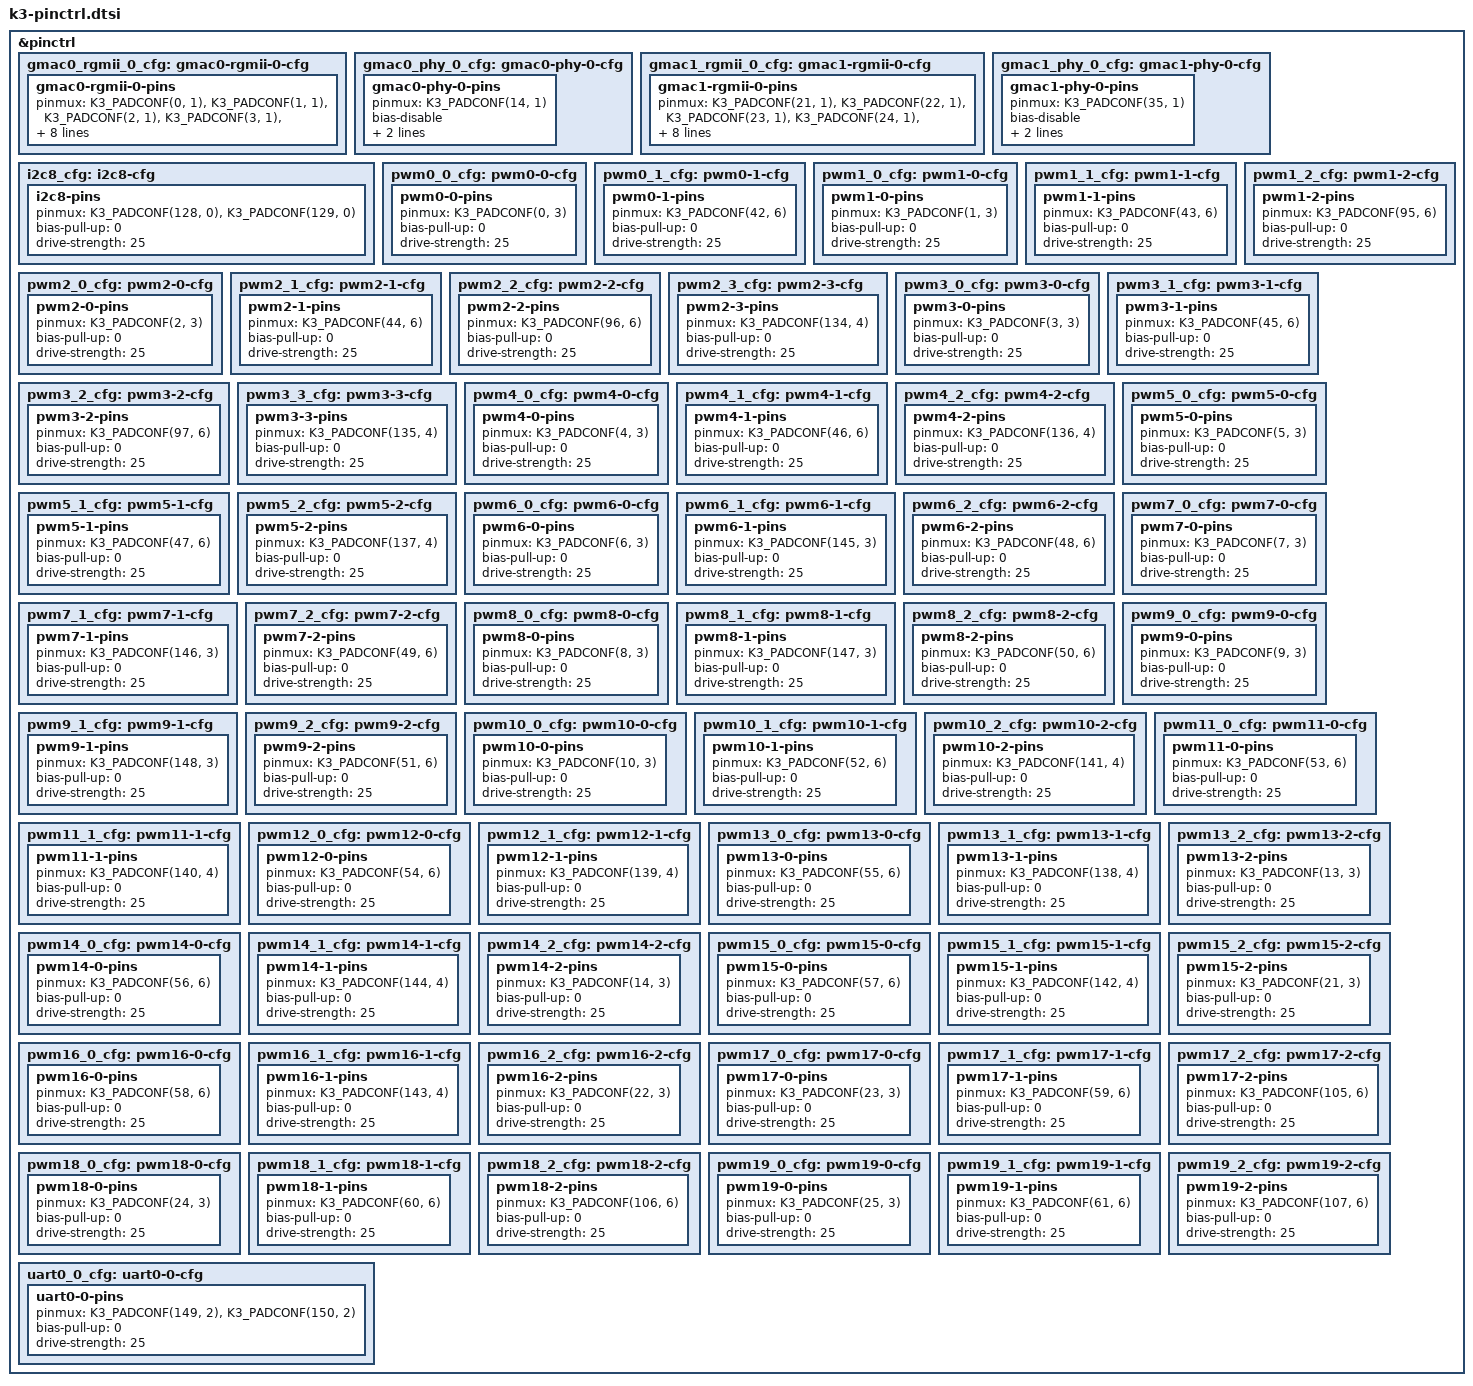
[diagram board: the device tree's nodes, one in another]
// SPDX-License-Identifier: GPL-2.0 OR MIT
/*
 * Copyright (c) 2026 Yixun Lan <dlan@kernel.org>
 */

#include <dt-bindings/gpio/gpio.h>

#define K3_PADCONF(pin, func) (((pin) << 16) | (func))

/* Map GPIO pin to each bank's <index, offset> */
#define K3_GPIO(x)	(x / 32) (x % 32)

&pinctrl {
	gmac0_rgmii_0_cfg: gmac0-rgmii-0-cfg {
		gmac0-rgmii-0-pins {
			pinmux = <K3_PADCONF(0, 1)>,	/* gmac0_rxdv */
				 <K3_PADCONF(1, 1)>,	/* gmac0_rx_d0 */
				 <K3_PADCONF(2, 1)>,	/* gmac0_rx_d1 */
				 <K3_PADCONF(3, 1)>,	/* gmac0_rx_clk */
				 <K3_PADCONF(4, 1)>,	/* gmac0_rx_d2 */
				 <K3_PADCONF(5, 1)>,	/* gmac0_rx_d3 */
				 <K3_PADCONF(6, 1)>,	/* gmac0_tx_d0 */
				 <K3_PADCONF(7, 1)>,	/* gmac0_tx_d1 */
				 <K3_PADCONF(8, 1)>,	/* gmac0_tx_clk */
				 <K3_PADCONF(9, 1)>,	/* gmac0_tx_d2 */
				 <K3_PADCONF(10, 1)>,	/* gmac0_tx_d3 */
				 <K3_PADCONF(11, 1)>,	/* gmac0_tx_en */
				 <K3_PADCONF(12, 1)>,	/* gmac0_mdc */
				 <K3_PADCONF(13, 1)>;	/* gmac0_mdio */

			bias-disable;
			drive-strength = <25>;
			power-source = <1800>;
		};

	};

	gmac0_phy_0_cfg: gmac0-phy-0-cfg {
		gmac0-phy-0-pins {
			pinmux = <K3_PADCONF(14, 1)>;   /* gmac0_int */

			bias-disable;
			drive-strength = <25>;
			power-source = <1800>;
		};
	};

	gmac1_rgmii_0_cfg: gmac1-rgmii-0-cfg {
		gmac1-rgmii-0-pins {
			pinmux = <K3_PADCONF(21, 1)>,	/* gmac1_rxdv  */
				 <K3_PADCONF(22, 1)>,	/* gmac1 rx d0 */
				 <K3_PADCONF(23, 1)>,	/* gmac1 rx d1 */
				 <K3_PADCONF(24, 1)>,	/* gmac1 rx_clk */
				 <K3_PADCONF(25, 1)>,	/* gmac1 rx d2 */
				 <K3_PADCONF(26, 1)>,	/* gmac1 rx d3 */
				 <K3_PADCONF(27, 1)>,	/* gmac1 tx d0 */
				 <K3_PADCONF(28, 1)>,	/* gmac1 tx d1 */
				 <K3_PADCONF(29, 1)>,	/* gmac1 tx clk */
				 <K3_PADCONF(30, 1)>,	/* gmac1 tx d2 */
				 <K3_PADCONF(31, 1)>,	/* gmac1 tx d3 */
				 <K3_PADCONF(32, 1)>,	/* gmac1 tx_en */
				 <K3_PADCONF(33, 1)>,	/* gmac1 mdc */
				 <K3_PADCONF(34, 1)>;	/* gmac1 mdio */

			bias-disable;
			drive-strength = <25>;
			power-source = <1800>;
		};
	};

	gmac1_phy_0_cfg: gmac1-phy-0-cfg {
		gmac1-phy-0-pins {
			pinmux = <K3_PADCONF(35, 1)>;	/* gmac1 int */

			bias-disable;
			drive-strength = <25>;
			power-source = <1800>;
		};
	};

	/omit-if-no-ref/
	i2c8_cfg: i2c8-cfg {
		i2c8-pins {
			pinmux = <K3_PADCONF(128, 0)>,	/* i2c8 scl */
				 <K3_PADCONF(129, 0)>;	/* i2c8 sda */

			bias-pull-up = <0>;
			drive-strength = <25>;
		};
	};

	/omit-if-no-ref/
	pwm0_0_cfg: pwm0-0-cfg {
		pwm0-0-pins {
			pinmux = <K3_PADCONF(0, 3)>;	/* pwm0 */

			bias-pull-up = <0>;
			drive-strength = <25>;
		};
	};

	/omit-if-no-ref/
	pwm0_1_cfg: pwm0-1-cfg {
		pwm0-1-pins {
			pinmux = <K3_PADCONF(42, 6)>;	/* pwm0 */

			bias-pull-up = <0>;
			drive-strength = <25>;
		};
	};

	/omit-if-no-ref/
	pwm1_0_cfg: pwm1-0-cfg {
		pwm1-0-pins {
			pinmux = <K3_PADCONF(1, 3)>;	/* pwm1 */

			bias-pull-up = <0>;
			drive-strength = <25>;
		};
	};

	/omit-if-no-ref/
	pwm1_1_cfg: pwm1-1-cfg {
		pwm1-1-pins {
			pinmux = <K3_PADCONF(43, 6)>;	/* pwm1 */

			bias-pull-up = <0>;
			drive-strength = <25>;
		};
	};

	/omit-if-no-ref/
	pwm1_2_cfg: pwm1-2-cfg {
		pwm1-2-pins {
			pinmux = <K3_PADCONF(95, 6)>;	/* pwm1 */

			bias-pull-up = <0>;
			drive-strength = <25>;
		};
	};

	/omit-if-no-ref/
	pwm2_0_cfg: pwm2-0-cfg {
		pwm2-0-pins {
			pinmux = <K3_PADCONF(2, 3)>;	/* pwm2 */

			bias-pull-up = <0>;
			drive-strength = <25>;
		};
	};

	/omit-if-no-ref/
	pwm2_1_cfg: pwm2-1-cfg {
		pwm2-1-pins {
			pinmux = <K3_PADCONF(44, 6)>;	/* pwm2 */

			bias-pull-up = <0>;
			drive-strength = <25>;
		};
	};

	/omit-if-no-ref/
	pwm2_2_cfg: pwm2-2-cfg {
		pwm2-2-pins {
			pinmux = <K3_PADCONF(96, 6)>;	/* pwm2 */

			bias-pull-up = <0>;
			drive-strength = <25>;
		};
	};

	/omit-if-no-ref/
	pwm2_3_cfg: pwm2-3-cfg {
		pwm2-3-pins {
			pinmux = <K3_PADCONF(134, 4)>;	/* pwm2 */

			bias-pull-up = <0>;
			drive-strength = <25>;
		};
	};

	/omit-if-no-ref/
	pwm3_0_cfg: pwm3-0-cfg {
		pwm3-0-pins {
			pinmux = <K3_PADCONF(3, 3)>;	/* pwm3 */

			bias-pull-up = <0>;
			drive-strength = <25>;
		};
	};

	/omit-if-no-ref/
	pwm3_1_cfg: pwm3-1-cfg {
		pwm3-1-pins {
			pinmux = <K3_PADCONF(45, 6)>;	/* pwm3 */

			bias-pull-up = <0>;
			drive-strength = <25>;
		};
	};

	/omit-if-no-ref/
	pwm3_2_cfg: pwm3-2-cfg {
		pwm3-2-pins {
			pinmux = <K3_PADCONF(97, 6)>;	/* pwm3 */

			bias-pull-up = <0>;
			drive-strength = <25>;
		};
	};

	/omit-if-no-ref/
	pwm3_3_cfg: pwm3-3-cfg {
		pwm3-3-pins {
			pinmux = <K3_PADCONF(135, 4)>;	/* pwm3 */

			bias-pull-up = <0>;
			drive-strength = <25>;
		};
	};

	/omit-if-no-ref/
	pwm4_0_cfg: pwm4-0-cfg {
		pwm4-0-pins {
			pinmux = <K3_PADCONF(4, 3)>;	/* pwm4 */

			bias-pull-up = <0>;
			drive-strength = <25>;
		};
	};

	/omit-if-no-ref/
	pwm4_1_cfg: pwm4-1-cfg {
		pwm4-1-pins {
			pinmux = <K3_PADCONF(46, 6)>;	/* pwm4 */

			bias-pull-up = <0>;
			drive-strength = <25>;
		};
	};

	/omit-if-no-ref/
	pwm4_2_cfg: pwm4-2-cfg {
		pwm4-2-pins {
			pinmux = <K3_PADCONF(136, 4)>;	/* pwm4 */

			bias-pull-up = <0>;
			drive-strength = <25>;
		};
	};

	/omit-if-no-ref/
	pwm5_0_cfg: pwm5-0-cfg {
		pwm5-0-pins {
			pinmux = <K3_PADCONF(5, 3)>;	/* pwm5 */

			bias-pull-up = <0>;
			drive-strength = <25>;
		};
	};

	/omit-if-no-ref/
	pwm5_1_cfg: pwm5-1-cfg {
		pwm5-1-pins {
			pinmux = <K3_PADCONF(47, 6)>;	/* pwm5 */

			bias-pull-up = <0>;
			drive-strength = <25>;
		};
	};

	/omit-if-no-ref/
	pwm5_2_cfg: pwm5-2-cfg {
		pwm5-2-pins {
			pinmux = <K3_PADCONF(137, 4)>;	/* pwm5 */

			bias-pull-up = <0>;
			drive-strength = <25>;
		};
	};

	/omit-if-no-ref/
	pwm6_0_cfg: pwm6-0-cfg {
		pwm6-0-pins {
			pinmux = <K3_PADCONF(6, 3)>;	/* pwm6 */

			bias-pull-up = <0>;
			drive-strength = <25>;
		};
	};

	/omit-if-no-ref/
	pwm6_1_cfg: pwm6-1-cfg {
		pwm6-1-pins {
			pinmux = <K3_PADCONF(145, 3)>;	/* pwm6 */

			bias-pull-up = <0>;
			drive-strength = <25>;
		};
	};

	/omit-if-no-ref/
	pwm6_2_cfg: pwm6-2-cfg {
		pwm6-2-pins {
			pinmux = <K3_PADCONF(48, 6)>;	/* pwm6 */

			bias-pull-up = <0>;
			drive-strength = <25>;
		};
	};

	/omit-if-no-ref/
	pwm7_0_cfg: pwm7-0-cfg {
		pwm7-0-pins {
			pinmux = <K3_PADCONF(7, 3)>;	/* pwm7 */

			bias-pull-up = <0>;
			drive-strength = <25>;
		};
	};

	/omit-if-no-ref/
	pwm7_1_cfg: pwm7-1-cfg {
		pwm7-1-pins {
			pinmux = <K3_PADCONF(146, 3)>;	/* pwm7 */

			bias-pull-up = <0>;
			drive-strength = <25>;
		};
	};

	/omit-if-no-ref/
	pwm7_2_cfg: pwm7-2-cfg {
		pwm7-2-pins {
			pinmux = <K3_PADCONF(49, 6)>;	/* pwm7 */

			bias-pull-up = <0>;
			drive-strength = <25>;
		};
	};

	/omit-if-no-ref/
	pwm8_0_cfg: pwm8-0-cfg {
		pwm8-0-pins {
			pinmux = <K3_PADCONF(8, 3)>;	/* pwm8 */

			bias-pull-up = <0>;
			drive-strength = <25>;
		};
	};

	/omit-if-no-ref/
	pwm8_1_cfg: pwm8-1-cfg {
		pwm8-1-pins {
			pinmux = <K3_PADCONF(147, 3)>;	/* pwm8 */

			bias-pull-up = <0>;
			drive-strength = <25>;
		};
	};

	/omit-if-no-ref/
	pwm8_2_cfg: pwm8-2-cfg {
		pwm8-2-pins {
			pinmux = <K3_PADCONF(50, 6)>;	/* pwm8 */

			bias-pull-up = <0>;
			drive-strength = <25>;
		};
	};

	/omit-if-no-ref/
	pwm9_0_cfg: pwm9-0-cfg {
		pwm9-0-pins {
			pinmux = <K3_PADCONF(9, 3)>;	/* pwm9 */

			bias-pull-up = <0>;
			drive-strength = <25>;
		};
	};

	/omit-if-no-ref/
	pwm9_1_cfg: pwm9-1-cfg {
		pwm9-1-pins {
			pinmux = <K3_PADCONF(148, 3)>;	/* pwm9 */

			bias-pull-up = <0>;
			drive-strength = <25>;
		};
	};

	/omit-if-no-ref/
	pwm9_2_cfg: pwm9-2-cfg {
		pwm9-2-pins {
			pinmux = <K3_PADCONF(51, 6)>;	/* pwm9 */

			bias-pull-up = <0>;
			drive-strength = <25>;
		};
	};

	/omit-if-no-ref/
	pwm10_0_cfg: pwm10-0-cfg {
		pwm10-0-pins {
			pinmux = <K3_PADCONF(10, 3)>;	/* pwm10 */

			bias-pull-up = <0>;
			drive-strength = <25>;
		};
	};

	/omit-if-no-ref/
	pwm10_1_cfg: pwm10-1-cfg {
		pwm10-1-pins {
			pinmux = <K3_PADCONF(52, 6)>;	/* pwm10 */

			bias-pull-up = <0>;
			drive-strength = <25>;
		};
	};

	/omit-if-no-ref/
	pwm10_2_cfg: pwm10-2-cfg {
		pwm10-2-pins {
			pinmux = <K3_PADCONF(141, 4)>;	/* pwm10 */

			bias-pull-up = <0>;
			drive-strength = <25>;
		};
	};

	/omit-if-no-ref/
	pwm11_0_cfg: pwm11-0-cfg {
		pwm11-0-pins {
			pinmux = <K3_PADCONF(53, 6)>;	/* pwm11 */

			bias-pull-up = <0>;
			drive-strength = <25>;
		};
	};

	/omit-if-no-ref/
	pwm11_1_cfg: pwm11-1-cfg {
		pwm11-1-pins {
			pinmux = <K3_PADCONF(140, 4)>;	/* pwm11 */

			bias-pull-up = <0>;
			drive-strength = <25>;
		};
	};

	/omit-if-no-ref/
	pwm12_0_cfg: pwm12-0-cfg {
		pwm12-0-pins {
			pinmux = <K3_PADCONF(54, 6)>;	/* pwm12 */

			bias-pull-up = <0>;
			drive-strength = <25>;
		};
	};

	/omit-if-no-ref/
	pwm12_1_cfg: pwm12-1-cfg {
		pwm12-1-pins {
			pinmux = <K3_PADCONF(139, 4)>;	/* pwm12 */

			bias-pull-up = <0>;
			drive-strength = <25>;
		};
	};

	/omit-if-no-ref/
	pwm13_0_cfg: pwm13-0-cfg {
		pwm13-0-pins {
			pinmux = <K3_PADCONF(55, 6)>;	/* pwm13 */

			bias-pull-up = <0>;
			drive-strength = <25>;
		};
	};

	/omit-if-no-ref/
	pwm13_1_cfg: pwm13-1-cfg {
		pwm13-1-pins {
			pinmux = <K3_PADCONF(138, 4)>;	/* pwm13 */

			bias-pull-up = <0>;
			drive-strength = <25>;
		};
	};

	/omit-if-no-ref/
	pwm13_2_cfg: pwm13-2-cfg {
		pwm13-2-pins {
			pinmux = <K3_PADCONF(13, 3)>;	/* pwm13 */

			bias-pull-up = <0>;
			drive-strength = <25>;
		};
	};

	/omit-if-no-ref/
	pwm14_0_cfg: pwm14-0-cfg {
		pwm14-0-pins {
			pinmux = <K3_PADCONF(56, 6)>;	/* pwm14 */

			bias-pull-up = <0>;
			drive-strength = <25>;
		};
	};

	/omit-if-no-ref/
	pwm14_1_cfg: pwm14-1-cfg {
		pwm14-1-pins {
			pinmux = <K3_PADCONF(144, 4)>;	/* pwm14 */

			bias-pull-up = <0>;
			drive-strength = <25>;
		};
	};

	/omit-if-no-ref/
	pwm14_2_cfg: pwm14-2-cfg {
		pwm14-2-pins {
			pinmux = <K3_PADCONF(14, 3)>;	/* pwm14 */

			bias-pull-up = <0>;
			drive-strength = <25>;
		};
	};

	/omit-if-no-ref/
	pwm15_0_cfg: pwm15-0-cfg {
		pwm15-0-pins {
			pinmux = <K3_PADCONF(57, 6)>;	/* pwm15 */

			bias-pull-up = <0>;
			drive-strength = <25>;
		};
	};

	/omit-if-no-ref/
	pwm15_1_cfg: pwm15-1-cfg {
		pwm15-1-pins {
			pinmux = <K3_PADCONF(142, 4)>;	/* pwm15 */

			bias-pull-up = <0>;
			drive-strength = <25>;
		};
	};

	/omit-if-no-ref/
	pwm15_2_cfg: pwm15-2-cfg {
		pwm15-2-pins {
			pinmux = <K3_PADCONF(21, 3)>;	/* pwm15 */

			bias-pull-up = <0>;
			drive-strength = <25>;
		};
	};

	/omit-if-no-ref/
	pwm16_0_cfg: pwm16-0-cfg {
		pwm16-0-pins {
			pinmux = <K3_PADCONF(58, 6)>;	/* pwm16 */

			bias-pull-up = <0>;
			drive-strength = <25>;
		};
	};

	/omit-if-no-ref/
	pwm16_1_cfg: pwm16-1-cfg {
		pwm16-1-pins {
			pinmux = <K3_PADCONF(143, 4)>;	/* pwm16 */

			bias-pull-up = <0>;
			drive-strength = <25>;
		};
	};

	/omit-if-no-ref/
	pwm16_2_cfg: pwm16-2-cfg {
		pwm16-2-pins {
			pinmux = <K3_PADCONF(22, 3)>;	/* pwm16 */

			bias-pull-up = <0>;
			drive-strength = <25>;
		};
	};

	/omit-if-no-ref/
	pwm17_0_cfg: pwm17-0-cfg {
		pwm17-0-pins {
			pinmux = <K3_PADCONF(23, 3)>;	/* pwm17 */

			bias-pull-up = <0>;
			drive-strength = <25>;
		};
	};

	/omit-if-no-ref/
	pwm17_1_cfg: pwm17-1-cfg {
		pwm17-1-pins {
			pinmux = <K3_PADCONF(59, 6)>;	/* pwm17 */

			bias-pull-up = <0>;
			drive-strength = <25>;
		};
	};

	/omit-if-no-ref/
	pwm17_2_cfg: pwm17-2-cfg {
		pwm17-2-pins {
			pinmux = <K3_PADCONF(105, 6)>;	/* pwm17 */

			bias-pull-up = <0>;
			drive-strength = <25>;
		};
	};

	/omit-if-no-ref/
	pwm18_0_cfg: pwm18-0-cfg {
		pwm18-0-pins {
			pinmux = <K3_PADCONF(24, 3)>;	/* pwm18 */

			bias-pull-up = <0>;
			drive-strength = <25>;
		};
	};

	/omit-if-no-ref/
	pwm18_1_cfg: pwm18-1-cfg {
		pwm18-1-pins {
			pinmux = <K3_PADCONF(60, 6)>;	/* pwm18 */

			bias-pull-up = <0>;
			drive-strength = <25>;
		};
	};

	/omit-if-no-ref/
	pwm18_2_cfg: pwm18-2-cfg {
		pwm18-2-pins {
			pinmux = <K3_PADCONF(106, 6)>;	/* pwm18 */

			bias-pull-up = <0>;
			drive-strength = <25>;
		};
	};

	/omit-if-no-ref/
	pwm19_0_cfg: pwm19-0-cfg {
		pwm19-0-pins {
			pinmux = <K3_PADCONF(25, 3)>;	/* pwm19 */

			bias-pull-up = <0>;
			drive-strength = <25>;
		};
	};

	/omit-if-no-ref/
	pwm19_1_cfg: pwm19-1-cfg {
		pwm19-1-pins {
			pinmux = <K3_PADCONF(61, 6)>;	/* pwm19 */

			bias-pull-up = <0>;
			drive-strength = <25>;
		};
	};

	/omit-if-no-ref/
	pwm19_2_cfg: pwm19-2-cfg {
		pwm19-2-pins {
			pinmux = <K3_PADCONF(107, 6)>;	/* pwm19 */

			bias-pull-up = <0>;
			drive-strength = <25>;
		};
	};

	/omit-if-no-ref/
	uart0_0_cfg: uart0-0-cfg {
		uart0-0-pins {
			pinmux = <K3_PADCONF(149, 2)>,	/* uart0 tx */
				 <K3_PADCONF(150, 2)>;	/* uart0 rx */

			bias-pull-up = <0>;
			drive-strength = <25>;
		};
	};
};
